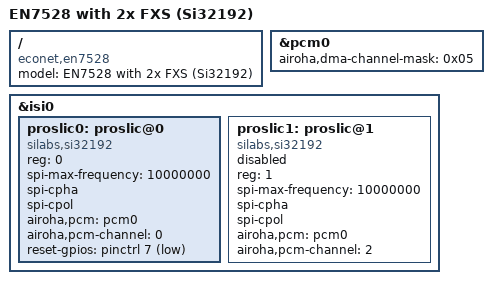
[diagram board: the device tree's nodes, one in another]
// SPDX-License-Identifier: GPL-2.0
/*
 * Example: EN7528 board with two FXS ports on a Skyworks Si32192
 * ProSLIC, reached over SPI.
 *
 * Modelled on the TP-Link XC220-G3v. The Si32192 is a two-channel
 * Si3219x, so one SPI device serves both lines: each line is a separate
 * node under the SPI controller only if the board fits two chips.
 * Here it is one chip, two channels.
 */

/dts-v1/;

#include <dt-bindings/gpio/gpio.h>

#include "en7528.dtsi"
#include "en7528-voice.dtsi"

/ {
	model = "EN7528 with 2x FXS (Si32192)";
	compatible = "econet,en7528";
};

&pcm0 {
	airoha,dma-channel-mask = <0x05>;
	status = "okay";
};

/*
 * ISI multiplexes the SLIC control channel onto the PCM pins (see isi0
 * in en7528-voice.dtsi); this is not the flash-shared &spi bus, and
 * docs/06-spi-shared-with-flash.md's flash-erase-disturbs-a-call
 * concern does not apply to it.
 *
 * Mode 3 (cpol = cpha = 1) at 10 MHz follows MediaTek's own ProSLIC
 * integration; the driver asks for SPI_MODE_3 in spi_setup() anyway,
 * so these mainly document intent and cap the clock.
 */
&isi0 {
	status = "okay";

	/*
	 * The wrapper's own channel-select register picks the device, not
	 * a real chip-select pin -- reg is 0 and 1 here, not offset by a
	 * shared flash chip select the way a real SPI bus would be.
	 */
	proslic0: proslic@0 {
		compatible = "silabs,si32192";
		reg = <0>;
		spi-max-frequency = <10000000>;
		spi-cpha;
		spi-cpol;

		airoha,pcm = <&pcm0>;
		airoha,pcm-channel = <0>;

		reset-gpios = <&pinctrl 7 GPIO_ACTIVE_LOW>;

		status = "okay";
	};

	proslic1: proslic@1 {
		compatible = "silabs,si32192";
		reg = <1>;
		spi-max-frequency = <10000000>;
		spi-cpha;
		spi-cpol;

		airoha,pcm = <&pcm0>;
		airoha,pcm-channel = <2>;

		/*
		 * A second physical device on the same ISI bus needs the
		 * chip-SCU DEV2 bits too -- see en75xx_isi_spi.c's file
		 * header. Untested with two devices present; leave disabled
		 * until that is verified on real hardware. (Also unresolved,
		 * inherited from before this file's transport fix: whether
		 * this board's two lines are truly two physical chips or two
		 * channels of one Si32192, which is not the same thing and
		 * this driver's channel_ptrs[1] currently only handles the
		 * latter as channel 0. Not an ISI-transport question.)
		 */
		status = "disabled";
	};
};
